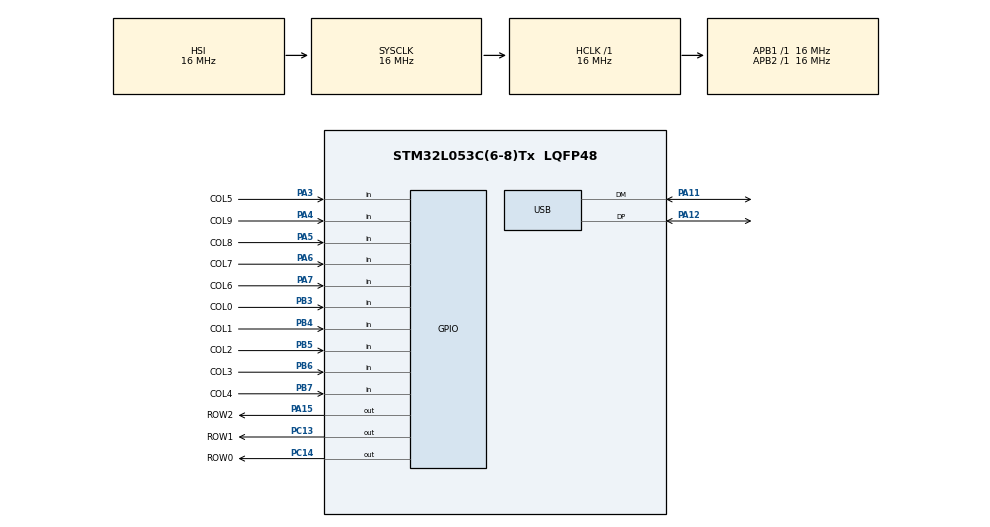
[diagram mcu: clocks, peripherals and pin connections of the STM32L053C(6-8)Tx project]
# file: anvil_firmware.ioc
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Mcu.Family=STM32L0
Mcu.Name=STM32L053C(6-8)Tx
Mcu.Package=LQFP48
NVIC.USB_IRQn=true\:0\:0\:false\:false\:true\:false\:true\:true
PA11.Mode=Device
PA11.Signal=USB_DM
PA12.Mode=Device
PA12.Signal=USB_DP
PA13.Mode=Serial_Wire
PA13.Signal=SYS_SWDIO
PA14.Mode=Serial_Wire
PA14.Signal=SYS_SWCLK
PA15.GPIO_Label=ROW2
PA15.Signal=GPIO_Output
PA3.GPIO_Label=COL5
PA3.GPIO_PuPd=GPIO_PULLDOWN
PA3.Signal=GPIO_Input
PA4.GPIO_Label=COL9
PA4.GPIO_PuPd=GPIO_PULLDOWN
PA4.Signal=GPIO_Input
PA5.GPIO_Label=COL8
PA5.GPIO_PuPd=GPIO_PULLDOWN
PA5.Signal=GPIO_Input
PA6.GPIO_Label=COL7
PA6.GPIO_PuPd=GPIO_PULLDOWN
PA6.Signal=GPIO_Input
PA7.GPIO_Label=COL6
PA7.GPIO_PuPd=GPIO_PULLDOWN
PA7.Signal=GPIO_Input
PB3.GPIO_Label=COL0
PB3.GPIO_PuPd=GPIO_PULLDOWN
PB3.Signal=GPIO_Input
PB4.GPIO_Label=COL1
PB4.GPIO_PuPd=GPIO_PULLDOWN
PB4.Signal=GPIO_Input
PB5.GPIO_Label=COL2
PB5.GPIO_PuPd=GPIO_PULLDOWN
PB5.Signal=GPIO_Input
PB6.GPIO_Label=COL3
PB6.GPIO_PuPd=GPIO_PULLDOWN
PB6.Signal=GPIO_Input
PB7.GPIO_Label=COL4
PB7.GPIO_PuPd=GPIO_PULLDOWN
PB7.Signal=GPIO_Input
PC13.GPIO_Label=ROW1
PC13.Signal=GPIO_Output
PC14-OSC32_IN.GPIO_Label=ROW0
PC14-OSC32_IN.Signal=GPIO_Output
ProjectManager.HeapSize=0x200
ProjectManager.StackSize=0x400
ProjectManager.TargetToolchain=STM32CubeIDE
RCC.AHBFreq_Value=16000000
RCC.APB1Freq_Value=16000000
RCC.APB1TimFreq_Value=16000000
RCC.APB2Freq_Value=16000000
RCC.APB2TimFreq_Value=16000000
RCC.HCLKFreq_Value=16000000
RCC.HSE_VALUE=8000000
RCC.HSI16_VALUE=16000000
RCC.HSI48MClockSelection=RCC_USBCLKSOURCE_HSI48
RCC.HSI48_VALUE=48000000
RCC.HSI_VALUE=16000000
RCC.LSE_VALUE=32768
RCC.MSI_VALUE=2097000
RCC.PLLMUL=RCC_PLLMUL_6
RCC.SYSCLKFreq_VALUE=16000000
RCC.SYSCLKSource=RCC_SYSCLKSOURCE_HSI
RCC.VCOOutputFreq_Value=96000000
USB_DEVICE.CLASS_NAME_FS=HID
USB_DEVICE.USBD_SELF_POWERED=0
USB_DEVICE.VirtualMode=Hid
USB_DEVICE.VirtualModeFS=Hid_FS
VP_USB_DEVICE_VS_USB_DEVICE_HID_FS.Mode=HID_FS
board=custom

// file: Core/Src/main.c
/* USER CODE BEGIN Header */
/**
  ******************************************************************************
  * @file           : main.c
  * @brief          : Main program body
  ******************************************************************************
  * @attention
  *
  * Copyright (c) 2024 STMicroelectronics.
  * All rights reserved.
  *
  * This software is licensed under terms that can be found in the LICENSE file
  * in the root directory of this software component.
  * If no LICENSE file comes with this software, it is provided AS-IS.
  *
  ******************************************************************************
  */
/* USER CODE END Header */
#include "main.h"
#include "usb_device.h"

/* USER CODE BEGIN Includes */
#include "keyboard.h"

/* USER CODE END Includes */

void SystemClock_Config(void);
static void MX_GPIO_Init(void);

int main(void)
{

  /* MCU Configuration--------------------------------------------------------*/

  /* Reset of all peripherals, Initializes the Flash interface and the Systick. */
  HAL_Init();

  /* Configure the system clock */
  SystemClock_Config();

  /* Initialize all configured peripherals */
  MX_GPIO_Init();
  MX_USB_DEVICE_Init();

  /* Infinite loop */
  /* USER CODE BEGIN WHILE */
  while (1)
  {
	  keybord_loop();
    /* USER CODE END WHILE */

  }
}

void SystemClock_Config(void)
{
  RCC_OscInitTypeDef RCC_OscInitStruct = {0};
  RCC_ClkInitTypeDef RCC_ClkInitStruct = {0};
  RCC_PeriphCLKInitTypeDef PeriphClkInit = {0};

  /** Configure the main internal regulator output voltage
  */
  __HAL_PWR_VOLTAGESCALING_CONFIG(PWR_REGULATOR_VOLTAGE_SCALE1);

  /** Initializes the RCC Oscillators according to the specified parameters
  * in the RCC_OscInitTypeDef structure.
  */
  RCC_OscInitStruct.OscillatorType = RCC_OSCILLATORTYPE_HSI|RCC_OSCILLATORTYPE_HSI48;
  RCC_OscInitStruct.HSIState = RCC_HSI_ON;
  RCC_OscInitStruct.HSICalibrationValue = RCC_HSICALIBRATION_DEFAULT;
  RCC_OscInitStruct.HSI48State = RCC_HSI48_ON;
  RCC_OscInitStruct.PLL.PLLState = RCC_PLL_NONE;
  if (HAL_RCC_OscConfig(&RCC_OscInitStruct) != HAL_OK)
  {
    Error_Handler();
  }

  /** Initializes the CPU, AHB and APB buses clocks
  */
  RCC_ClkInitStruct.ClockType = RCC_CLOCKTYPE_HCLK|RCC_CLOCKTYPE_SYSCLK
                              |RCC_CLOCKTYPE_PCLK1|RCC_CLOCKTYPE_PCLK2;
  RCC_ClkInitStruct.SYSCLKSource = RCC_SYSCLKSOURCE_HSI;
  RCC_ClkInitStruct.AHBCLKDivider = RCC_SYSCLK_DIV1;
  RCC_ClkInitStruct.APB1CLKDivider = RCC_HCLK_DIV1;
  RCC_ClkInitStruct.APB2CLKDivider = RCC_HCLK_DIV1;

  if (HAL_RCC_ClockConfig(&RCC_ClkInitStruct, FLASH_LATENCY_0) != HAL_OK)
  {
    Error_Handler();
  }
  PeriphClkInit.PeriphClockSelection = RCC_PERIPHCLK_USB;
  PeriphClkInit.UsbClockSelection = RCC_USBCLKSOURCE_HSI48;
  if (HAL_RCCEx_PeriphCLKConfig(&PeriphClkInit) != HAL_OK)
  {
    Error_Handler();
  }
}

static void MX_GPIO_Init(void)
{
  GPIO_InitTypeDef GPIO_InitStruct = {0};

  /* GPIO Ports Clock Enable */
  __HAL_RCC_GPIOC_CLK_ENABLE();
  __HAL_RCC_GPIOA_CLK_ENABLE();
  __HAL_RCC_GPIOB_CLK_ENABLE();

  /*Configure GPIO pin Output Level */
  HAL_GPIO_WritePin(GPIOC, ROW1_Pin|ROW0_Pin, GPIO_PIN_RESET);

  /*Configure GPIO pin Output Level */
  HAL_GPIO_WritePin(ROW2_GPIO_Port, ROW2_Pin, GPIO_PIN_RESET);

  /*Configure GPIO pins : ROW1_Pin ROW0_Pin */
  GPIO_InitStruct.Pin = ROW1_Pin|ROW0_Pin;
  GPIO_InitStruct.Mode = GPIO_MODE_OUTPUT_PP;
  GPIO_InitStruct.Pull = GPIO_NOPULL;
  GPIO_InitStruct.Speed = GPIO_SPEED_FREQ_LOW;
  HAL_GPIO_Init(GPIOC, &GPIO_InitStruct);

  /*Configure GPIO pins : COL5_Pin COL9_Pin COL8_Pin COL7_Pin
                           COL6_Pin */
  GPIO_InitStruct.Pin = COL5_Pin|COL9_Pin|COL8_Pin|COL7_Pin
                          |COL6_Pin;
  GPIO_InitStruct.Mode = GPIO_MODE_INPUT;
  GPIO_InitStruct.Pull = GPIO_PULLDOWN;
  HAL_GPIO_Init(GPIOA, &GPIO_InitStruct);

  /*Configure GPIO pin : ROW2_Pin */
  GPIO_InitStruct.Pin = ROW2_Pin;
  GPIO_InitStruct.Mode = GPIO_MODE_OUTPUT_PP;
  GPIO_InitStruct.Pull = GPIO_NOPULL;
  GPIO_InitStruct.Speed = GPIO_SPEED_FREQ_LOW;
  HAL_GPIO_Init(ROW2_GPIO_Port, &GPIO_InitStruct);

  /*Configure GPIO pins : COL0_Pin COL1_Pin COL2_Pin COL3_Pin
                           COL4_Pin */
  GPIO_InitStruct.Pin = COL0_Pin|COL1_Pin|COL2_Pin|COL3_Pin
                          |COL4_Pin;
  GPIO_InitStruct.Mode = GPIO_MODE_INPUT;
  GPIO_InitStruct.Pull = GPIO_PULLDOWN;
  HAL_GPIO_Init(GPIOB, &GPIO_InitStruct);

}

void Error_Handler(void)
{
  __disable_irq();
  while (1)
  {
  }
}
